# EFR32FG23B010F512IM48 register map
Vendor: Silicon Labs; Series: EFR32; File version: C
CPU: CM33 r0p4, little endian, MPU, FPU, DSP, VTOR, 4 interrupt priority bits, 8 SAU regions
Registers are 32-bit, read-write, reset 0x0 unless marked. A register's access mark holds for its fields unless they carry their own. Offsets are from the block's base; [hi:lo] are bit positions; {n}, {i} and the like mark numbered series; 'fields as' and 'values as' point back to an identical list.

## LDMA_NS — LDMA_NS Registers
Base 0x50040000
Same registers: LDMA_S 0x40040000
0x00 IPVERSION ro
  [7:0] IPVERSION
0x04 EN
  [0] EN — LDMA module enable and disable register
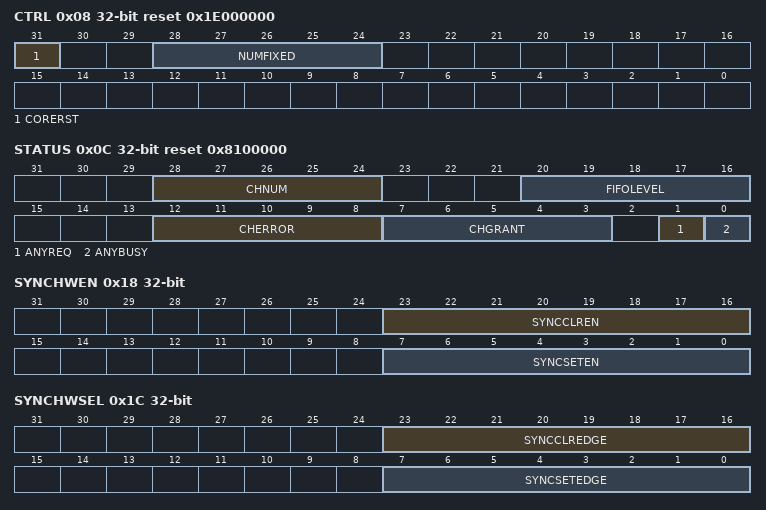
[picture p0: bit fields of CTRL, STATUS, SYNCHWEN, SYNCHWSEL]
0x08 CTRL reset 0x1E000000
  [31] CORERST — Reset DMA controller
  [28:24] NUMFIXED — Number of Fixed Priority Channels
0x0C STATUS ro reset 0x8100000
  [28:24] CHNUM — Number of Channels
  [20:16] FIFOLEVEL
  [12:8] CHERROR — Errant Channel Number
  [7:3] CHGRANT — Granted Channel Number
  [1] ANYREQ — Any DMA Channel Request Pending
  [0] ANYBUSY — Any DMA Channel Busy
0x10 SYNCSWSET wo
  [7:0] SYNCSWSET — DMA SYNC Software Trigger Set
0x14 SYNCSWCLR wo
  [7:0] SYNCSWCLR — DMA SYNC Software Trigger Clear
0x18 SYNCHWEN
  [23:16] SYNCCLREN — Hardware Sync Trigger Clear Enable
  [7:0] SYNCSETEN — Hardware Sync Trigger Set Enable
0x1C SYNCHWSEL
  [23:16] SYNCCLREDGE — Hardware Sync Trigger Clear Edge Select
    0=RISE (Use rising edge detection); 1=FALL (Use falling edge detection)
  [7:0] SYNCSETEDGE — Hardware Sync Trigger Set Edge Select
    values as SYNCCLREDGE
0x20 SYNCSTATUS ro
  [7:0] SYNCTRIG — sync trig status
0x24 CHEN wo
  [7:0] CHEN — Channel Enables
0x28 CHDIS wo
  [7:0] CHDIS — DMA Channel disable
0x2C CHSTATUS ro
  [7:0] CHSTATUS — DMA Channel Status
0x30 CHBUSY ro
  [7:0] BUSY — Channels Busy
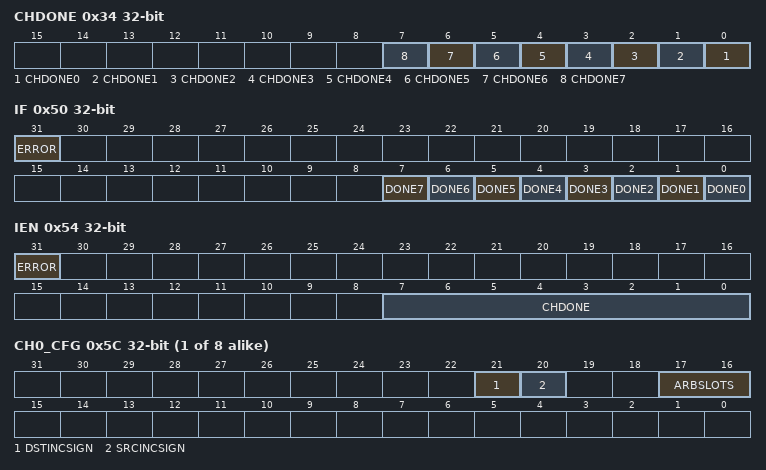
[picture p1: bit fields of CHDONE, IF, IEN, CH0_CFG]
0x34 CHDONE
  [n] CHDONE{n} (n=0..7) — DMA Channel Link done intr flag
0x38 DBGHALT
  [7:0] DBGHALT — DMA Debug Halt
0x3C SWREQ wo
  [7:0] SWREQ — Software Transfer Requests
0x40 REQDIS
  [7:0] REQDIS — DMA Request Disables
0x44 REQPEND ro
  [7:0] REQPEND — DMA Requests Pending
0x48 LINKLOAD wo
  [7:0] LINKLOAD — DMA Link Loads
0x4C REQCLEAR wo
  [7:0] REQCLEAR — DMA Request Clear
0x50 IF
  [31] ERROR — Error Flag
  [n] DONE{n} (n=0..7) — DMA Structure Operation Done
0x54 IEN
  [31] ERROR — Enable or disable the error interrupt
  [7:0] CHDONE — Enable or disable the done interrupt
{0x5C+0x30*i} CH{i}_CFG (i=0..7)
  [21] DSTINCSIGN — Destination Address Increment Sign
    0=POSITIVE (Increment destination address); 1=NEGATIVE (Decrement destination address)
  [20] SRCINCSIGN — Source Address Increment Sign
    0=POSITIVE (Increment source address); 1=NEGATIVE (Decrement source address)
  [17:16] ARBSLOTS — Arbitration Slot Number Select
    0=ONE (One arbitration slot selected); 1=TWO (Two arbitration slots selected); 2=FOUR (Four arbitration slots selected); 3=EIGHT (Eight arbitration slots selected)
{0x60+0x30*i} CH{i}_LOOP (i=0..7)
  [7:0] LOOPCNT — Linked Structure Sequence Loop Counter
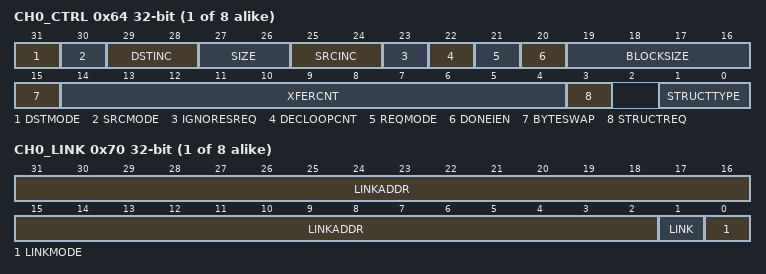
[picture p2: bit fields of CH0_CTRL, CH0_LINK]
{0x64+0x30*i} CH{i}_CTRL (i=0..7)
  [31] DSTMODE ro — Destination Addressing Mode
    0=ABSOLUTE (The DSTADDR field of LDMA_CHx_DST contains the absolute address of the destination data.); 1=RELATIVE (The DSTADDR field of LDMA_CHx_DST contains the relative offset of the destination data.)
  [30] SRCMODE ro — Source Addressing Mode
    0=ABSOLUTE (The SRCADDR field of LDMA_CHx_SRC contains the absolute address of the source data.); 1=RELATIVE (The SRCADDR field of LDMA_CHx_SRC contains the relative offset of the source data.)
  [29:28] DSTINC — Destination Address Increment Size
    0=ONE (Increment destination address by one unit data size after each write); 1=TWO (Increment destination address by two unit data sizes after each write); 2=FOUR (Increment destination address by four unit data sizes after each write); 3=NONE (Do not increment the destination address. Writes are made to a fixed destination address, for example writing to a FIFO.)
  [27:26] SIZE — Unit Data Transfer Size
    0=BYTE (Each unit transfer is a byte); 1=HALFWORD (Each unit transfer is a half-word); 2=WORD (Each unit transfer is a word)
  [25:24] SRCINC — Source Address Increment Size
    0=ONE (Increment source address by one unit data size after each read); 1=TWO (Increment source address by two unit data sizes after each read); 2=FOUR (Increment source address by four unit data sizes after each read); 3=NONE (Do not increment the source address. In this mode reads are made from a fixed source address, for example reading FIFO.)
  [23] IGNORESREQ
  [22] DECLOOPCNT — Decrement Loop Count
  [21] REQMODE — DMA Request Transfer Mode Select
    0=BLOCK (The LDMA transfers one BLOCKSIZE per transfer request.); 1=ALL (One transfer request transfers all units as defined by the XFRCNT field.)
  [20] DONEIEN — DMA Operation Done Interrupt Flag Set En
  [19:16] BLOCKSIZE — Block Transfer Size
    0=UNIT1 (One unit transfer per arbitration); 1=UNIT2 (Two unit transfers per arbitration); 2=UNIT3 (Three unit transfers per arbitration); 3=UNIT4 (Four unit transfers per arbitration); 4=UNIT6 (Six unit transfers per arbitration); 5=UNIT8 (Eight unit transfers per arbitration); 7=UNIT16 (Sixteen unit transfers per arbitration); 9=UNIT32 (32 unit transfers per arbitration); 10=UNIT64 (64 unit transfers per arbitration); 11=UNIT128 (128 unit transfers per arbitration); 12=UNIT256 (256 unit transfers per arbitration); 13=UNIT512 (512 unit transfers per arbitration); 14=UNIT1024 (1024 unit transfers per arbitration); 15=ALL (Transfer all units as specified by the XFRCNT field)
  [15] BYTESWAP — Endian Byte Swap
  [14:4] XFERCNT — DMA Unit Data Transfer Count
  [3] STRUCTREQ ro — Structure DMA Transfer Request
  [1:0] STRUCTTYPE — DMA Structure Type
    0=TRANSFER (DMA transfer structure type selected.); 1=SYNCHRONIZE (Synchronization structure type selected.); 2=WRITE (Write immediate value structure type selected.)
{0x68+0x30*i} CH{i}_SRC (i=0..7)
  [31:0] SRCADDR — Source Data Address
{0x6C+0x30*i} CH{i}_DST (i=0..7)
  [31:0] DSTADDR — Destination Data Address
{0x70+0x30*i} CH{i}_LINK (i=0..7)
  [31:2] LINKADDR — Link Structure Address
  [1] LINK — Link Next Structure
  [0] LINKMODE ro — Link Structure Addressing Mode
    0=ABSOLUTE (The LINKADDR field of LDMA_CHx_LINK contains the absolute address of the linked descriptor.); 1=RELATIVE (The LINKADDR field of LDMA_CHx_LINK contains the relative offset of the linked descriptor.)
